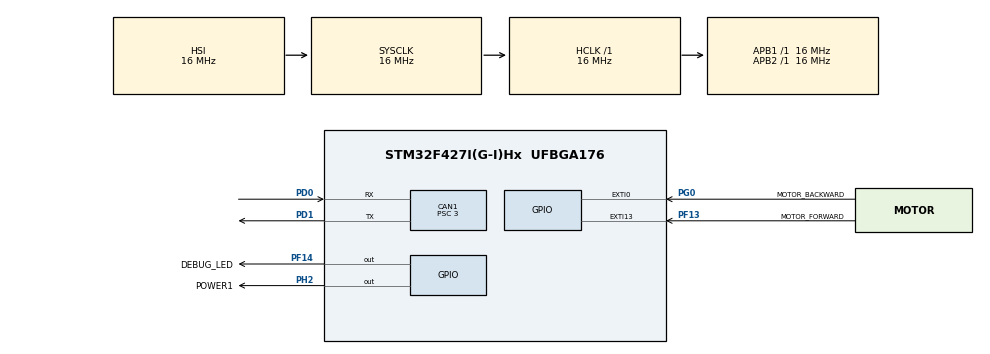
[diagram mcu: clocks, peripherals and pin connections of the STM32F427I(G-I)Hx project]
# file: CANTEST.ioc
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CAN1.ABOM=ENABLE
CAN1.BS1=CAN_BS1_9TQ
CAN1.BS2=CAN_BS2_4TQ
CAN1.CalculateTimeQuantum=187.5
CAN1.NART=ENABLE
CAN1.Prescaler=3
CAN1.SJW=CAN_SJW_1TQ
CAN1.TXFP=DISABLE
Mcu.Family=STM32F4
Mcu.Name=STM32F427I(G-I)Hx
Mcu.Package=UFBGA176
NVIC.CAN1_RX0_IRQn=true\:0\:0\:false\:false\:true\:true
NVIC.CAN1_TX_IRQn=true\:0\:0\:false\:false\:true\:true
NVIC.EXTI0_IRQn=true\:0\:0\:false\:false\:true\:true
NVIC.EXTI15_10_IRQn=true\:0\:0\:false\:false\:true\:true
NVIC.PriorityGroup=NVIC_PRIORITYGROUP_4
NVIC.TIM6_DAC_IRQn=true\:0\:0\:false\:false\:true\:true
PD0.Mode=Master
PD0.Signal=CAN1_RX
PD1.Mode=Master
PD1.Signal=CAN1_TX
PF13.GPIO_Label=MOTOR_FORWARD
PF13.GPIO_ModeDefaultEXTI=GPIO_MODE_IT_FALLING
PF13.GPIO_PuPd=GPIO_PULLUP
PF13.Signal=GPXTI13
PF14.GPIO_Label=DEBUG_LED
PF14.Signal=GPIO_Output
PG0.GPIO_Label=MOTOR_BACKWARD
PG0.GPIO_ModeDefaultEXTI=GPIO_MODE_IT_FALLING
PG0.GPIO_PuPd=GPIO_PULLUP
PG0.Signal=GPXTI0
PH2.GPIO_Label=POWER1
PH2.PinState=GPIO_PIN_SET
PH2.Signal=GPIO_Output
ProjectManager.HeapSize=0x200
ProjectManager.StackSize=0x400
ProjectManager.TargetToolchain=MDK-ARM V5
RCC.AHBFreq_Value=16000000
RCC.APB1Freq_Value=16000000
RCC.APB2Freq_Value=16000000
RCC.CortexFreq_Value=16000000
RCC.HSE_VALUE=25000000
RCC.HSI_VALUE=16000000
RCC.LSE_VALUE=32768
RCC.SYSCLKFreq_VALUE=16000000
RCC.VCOOutputFreq_Value=192000000
TIM6.Period=2000
TIM6.Prescaler=42
VP_TIM6_VS_ClockSourceINT.Mode=Enable_Timer
board=custom

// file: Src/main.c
/**
  ******************************************************************************
  * @file           : main.c
  * @brief          : Main program body
  ******************************************************************************
  ** This notice applies to any and all portions of this file
  * that are not between comment pairs USER CODE BEGIN and
  * USER CODE END. Other portions of this file, whether
  * inserted by the user or by software development tools
  * are owned by their respective copyright owners.
  *
  * COPYRIGHT(c) 2018 STMicroelectronics
  *
  * Redistribution and use in source and binary forms, with or without modification,
  * are permitted provided that the following conditions are met:
  *   1. Redistributions of source code must retain the above copyright notice,
  *      this list of conditions and the following disclaimer.
  *   2. Redistributions in binary form must reproduce the above copyright notice,
  *      this list of conditions and the following disclaimer in the documentation
  *      and/or other materials provided with the distribution.
  *   3. Neither the name of STMicroelectronics nor the names of its contributors
  *      may be used to endorse or promote products derived from this software
  *      without specific prior written permission.
  *
  * THIS SOFTWARE IS PROVIDED BY THE COPYRIGHT HOLDERS AND CONTRIBUTORS "AS IS"
  * AND ANY EXPRESS OR IMPLIED WARRANTIES, INCLUDING, BUT NOT LIMITED TO, THE
  * IMPLIED WARRANTIES OF MERCHANTABILITY AND FITNESS FOR A PARTICULAR PURPOSE ARE
  * DISCLAIMED. IN NO EVENT SHALL THE COPYRIGHT HOLDER OR CONTRIBUTORS BE LIABLE
  * FOR ANY DIRECT, INDIRECT, INCIDENTAL, SPECIAL, EXEMPLARY, OR CONSEQUENTIAL
  * DAMAGES (INCLUDING, BUT NOT LIMITED TO, PROCUREMENT OF SUBSTITUTE GOODS OR
  * SERVICES; LOSS OF USE, DATA, OR PROFITS; OR BUSINESS INTERRUPTION) HOWEVER
  * CAUSED AND ON ANY THEORY OF LIABILITY, WHETHER IN CONTRACT, STRICT LIABILITY,
  * OR TORT (INCLUDING NEGLIGENCE OR OTHERWISE) ARISING IN ANY WAY OUT OF THE USE
  * OF THIS SOFTWARE, EVEN IF ADVISED OF THE POSSIBILITY OF SUCH DAMAGE.
  *
  ******************************************************************************
  */
#include "main.h"
#include "stm32f4xx_hal.h"

/* USER CODE BEGIN Includes */
#include "bsp_can.h"
/* USER CODE END Includes */

CAN_HandleTypeDef hcan1;

TIM_HandleTypeDef htim6;

/* USER CODE BEGIN PV */
/* Private variables ---------------------------------------------------------*/

/* USER CODE END PV */

void SystemClock_Config(void);
static void MX_GPIO_Init(void);
static void MX_CAN1_Init(void);
static void MX_TIM6_Init(void);

/* USER CODE BEGIN PFP */
/* Private function prototypes -----------------------------------------------*/

/* USER CODE END PFP */

int main(void)
{

  /* MCU Configuration----------------------------------------------------------*/

  /* Reset of all peripherals, Initializes the Flash interface and the Systick. */
  HAL_Init();

  /* Configure the system clock */
  SystemClock_Config();

  /* Initialize all configured peripherals */
  MX_GPIO_Init();
  MX_CAN1_Init();
  MX_TIM6_Init();
  /* USER CODE BEGIN 2 */
	CAN_Init_All();
  /* USER CODE END 2 */

  /* Infinite loop */
	while (1)
  {

  /* USER CODE BEGIN 3 */
	HAL_Delay(50);
	ME_Test_Chassis(10000,10000,10000,10000);
  }
  /* USER CODE END 3 */

}

void SystemClock_Config(void)
{

  RCC_OscInitTypeDef RCC_OscInitStruct;
  RCC_ClkInitTypeDef RCC_ClkInitStruct;

    /**Configure the main internal regulator output voltage
    */
  __HAL_RCC_PWR_CLK_ENABLE();

  __HAL_PWR_VOLTAGESCALING_CONFIG(PWR_REGULATOR_VOLTAGE_SCALE3);

    /**Initializes the CPU, AHB and APB busses clocks
    */
  RCC_OscInitStruct.OscillatorType = RCC_OSCILLATORTYPE_HSI;
  RCC_OscInitStruct.HSIState = RCC_HSI_ON;
  RCC_OscInitStruct.HSICalibrationValue = 16;
  RCC_OscInitStruct.PLL.PLLState = RCC_PLL_NONE;
  if (HAL_RCC_OscConfig(&RCC_OscInitStruct) != HAL_OK)
  {
    _Error_Handler(__FILE__, __LINE__);
  }

    /**Initializes the CPU, AHB and APB busses clocks
    */
  RCC_ClkInitStruct.ClockType = RCC_CLOCKTYPE_HCLK|RCC_CLOCKTYPE_SYSCLK
                              |RCC_CLOCKTYPE_PCLK1|RCC_CLOCKTYPE_PCLK2;
  RCC_ClkInitStruct.SYSCLKSource = RCC_SYSCLKSOURCE_HSI;
  RCC_ClkInitStruct.AHBCLKDivider = RCC_SYSCLK_DIV1;
  RCC_ClkInitStruct.APB1CLKDivider = RCC_HCLK_DIV1;
  RCC_ClkInitStruct.APB2CLKDivider = RCC_HCLK_DIV1;

  if (HAL_RCC_ClockConfig(&RCC_ClkInitStruct, FLASH_LATENCY_0) != HAL_OK)
  {
    _Error_Handler(__FILE__, __LINE__);
  }

    /**Configure the Systick interrupt time
    */
  HAL_SYSTICK_Config(HAL_RCC_GetHCLKFreq()/1000);

    /**Configure the Systick
    */
  HAL_SYSTICK_CLKSourceConfig(SYSTICK_CLKSOURCE_HCLK);

  /* SysTick_IRQn interrupt configuration */
  HAL_NVIC_SetPriority(SysTick_IRQn, 0, 0);
}

/* CAN1 init function */
static void MX_CAN1_Init(void)
{

  hcan1.Instance = CAN1;
  hcan1.Init.Prescaler = 3;
  hcan1.Init.Mode = CAN_MODE_NORMAL;
  hcan1.Init.SyncJumpWidth = CAN_SJW_1TQ;
  hcan1.Init.TimeSeg1 = CAN_BS1_9TQ;
  hcan1.Init.TimeSeg2 = CAN_BS2_4TQ;
  hcan1.Init.TimeTriggeredMode = DISABLE;
  hcan1.Init.AutoBusOff = ENABLE;
  hcan1.Init.AutoWakeUp = DISABLE;
  hcan1.Init.AutoRetransmission = ENABLE;
  hcan1.Init.ReceiveFifoLocked = DISABLE;
  hcan1.Init.TransmitFifoPriority = DISABLE;
  if (HAL_CAN_Init(&hcan1) != HAL_OK)
  {
    _Error_Handler(__FILE__, __LINE__);
  }

}

/* TIM6 init function */
static void MX_TIM6_Init(void)
{

  TIM_MasterConfigTypeDef sMasterConfig;

  htim6.Instance = TIM6;
  htim6.Init.Prescaler = 42;
  htim6.Init.CounterMode = TIM_COUNTERMODE_UP;
  htim6.Init.Period = 2000;
  if (HAL_TIM_Base_Init(&htim6) != HAL_OK)
  {
    _Error_Handler(__FILE__, __LINE__);
  }

  sMasterConfig.MasterOutputTrigger = TIM_TRGO_RESET;
  sMasterConfig.MasterSlaveMode = TIM_MASTERSLAVEMODE_DISABLE;
  if (HAL_TIMEx_MasterConfigSynchronization(&htim6, &sMasterConfig) != HAL_OK)
  {
    _Error_Handler(__FILE__, __LINE__);
  }

}

/** Configure pins as
        * Analog
        * Input
        * Output
        * EVENT_OUT
        * EXTI
*/
static void MX_GPIO_Init(void)
{

  GPIO_InitTypeDef GPIO_InitStruct;

  /* GPIO Ports Clock Enable */
  __HAL_RCC_GPIOD_CLK_ENABLE();
  __HAL_RCC_GPIOH_CLK_ENABLE();
  __HAL_RCC_GPIOF_CLK_ENABLE();
  __HAL_RCC_GPIOG_CLK_ENABLE();

  /*Configure GPIO pin Output Level */
  HAL_GPIO_WritePin(POWER1_GPIO_Port, POWER1_Pin, GPIO_PIN_SET);

  /*Configure GPIO pin Output Level */
  HAL_GPIO_WritePin(DEBUG_LED_GPIO_Port, DEBUG_LED_Pin, GPIO_PIN_RESET);

  /*Configure GPIO pin : POWER1_Pin */
  GPIO_InitStruct.Pin = POWER1_Pin;
  GPIO_InitStruct.Mode = GPIO_MODE_OUTPUT_PP;
  GPIO_InitStruct.Pull = GPIO_NOPULL;
  GPIO_InitStruct.Speed = GPIO_SPEED_FREQ_LOW;
  HAL_GPIO_Init(POWER1_GPIO_Port, &GPIO_InitStruct);

  /*Configure GPIO pin : MOTOR_FORWARD_Pin */
  GPIO_InitStruct.Pin = MOTOR_FORWARD_Pin;
  GPIO_InitStruct.Mode = GPIO_MODE_IT_FALLING;
  GPIO_InitStruct.Pull = GPIO_PULLUP;
  HAL_GPIO_Init(MOTOR_FORWARD_GPIO_Port, &GPIO_InitStruct);

  /*Configure GPIO pin : MOTOR_BACKWARD_Pin */
  GPIO_InitStruct.Pin = MOTOR_BACKWARD_Pin;
  GPIO_InitStruct.Mode = GPIO_MODE_IT_FALLING;
  GPIO_InitStruct.Pull = GPIO_PULLUP;
  HAL_GPIO_Init(MOTOR_BACKWARD_GPIO_Port, &GPIO_InitStruct);

  /*Configure GPIO pin : DEBUG_LED_Pin */
  GPIO_InitStruct.Pin = DEBUG_LED_Pin;
  GPIO_InitStruct.Mode = GPIO_MODE_OUTPUT_PP;
  GPIO_InitStruct.Pull = GPIO_NOPULL;
  GPIO_InitStruct.Speed = GPIO_SPEED_FREQ_LOW;
  HAL_GPIO_Init(DEBUG_LED_GPIO_Port, &GPIO_InitStruct);

  /* EXTI interrupt init*/
  HAL_NVIC_SetPriority(EXTI0_IRQn, 0, 0);
  HAL_NVIC_EnableIRQ(EXTI0_IRQn);

  HAL_NVIC_SetPriority(EXTI15_10_IRQn, 0, 0);
  HAL_NVIC_EnableIRQ(EXTI15_10_IRQn);

}

void _Error_Handler(char *file, int line)
{
  while(1)
  {
  }
}

/************************ (C) COPYRIGHT STMicroelectronics *****END OF FILE****/
